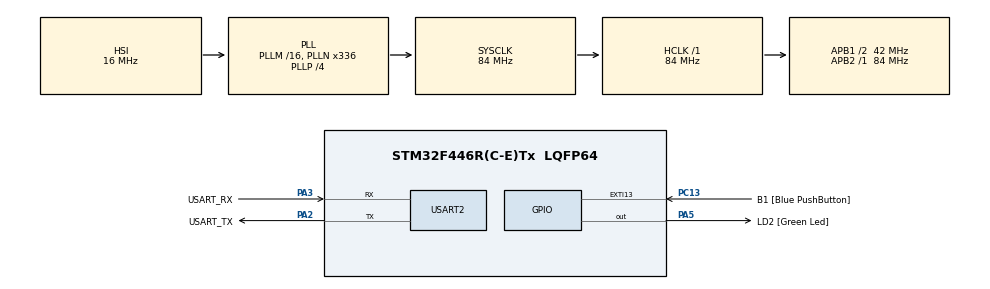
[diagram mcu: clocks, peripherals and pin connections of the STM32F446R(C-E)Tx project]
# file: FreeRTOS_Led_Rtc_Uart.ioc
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FREERTOS.Tasks01=defaultTask,24,128,StartDefaultTask,Default,NULL,Dynamic,NULL,NULL;LedTask,11,128,LedFunction,Default,NULL,Dynamic,NULL,NULL;RtcUartTask,32,128,RtcUartFunction,Default,NULL,Dynamic,NULL,NULL
FREERTOS.configUSE_NEWLIB_REENTRANT=1
Mcu.Family=STM32F4
Mcu.Name=STM32F446R(C-E)Tx
Mcu.Package=LQFP64
NVIC.PriorityGroup=NVIC_PRIORITYGROUP_4
NVIC.TIM5_IRQn=true\:15\:0\:false\:false\:true\:false\:false\:true
NVIC.TimeBase=TIM5_IRQn
NVIC.TimeBaseIP=TIM5
PA13.GPIO_Label=TMS
PA13.Mode=Serial_Wire
PA13.Signal=SYS_JTMS-SWDIO
PA14.GPIO_Label=TCK
PA14.Mode=Serial_Wire
PA14.Signal=SYS_JTCK-SWCLK
PA2.GPIO_Label=USART_TX
PA2.Mode=Asynchronous
PA2.Signal=USART2_TX
PA3.GPIO_Label=USART_RX
PA3.Mode=Asynchronous
PA3.Signal=USART2_RX
PA5.GPIO_Label=LD2 [Green Led]
PA5.Signal=GPIO_Output
PB3.GPIO_Label=SWO
PB3.Signal=SYS_JTDO-SWO
PC13.GPIO_Label=B1 [Blue PushButton]
PC13.GPIO_ModeDefaultEXTI=GPIO_MODE_IT_FALLING
PC13.Signal=GPXTI13
PC14-OSC32_IN.Mode=LSE-External-Oscillator
PC14-OSC32_IN.Signal=RCC_OSC32_IN
PC15-OSC32_OUT.Mode=LSE-External-Oscillator
PC15-OSC32_OUT.Signal=RCC_OSC32_OUT
PH0-OSC_IN.Signal=RCC_OSC_IN
PH1-OSC_OUT.Signal=RCC_OSC_OUT
ProjectManager.HeapSize=0x200
ProjectManager.StackSize=0x400
ProjectManager.TargetToolchain=STM32CubeIDE
RCC.AHBFreq_Value=84000000
RCC.APB1CLKDivider=RCC_HCLK_DIV2
RCC.APB1Freq_Value=42000000
RCC.APB1TimFreq_Value=84000000
RCC.APB2Freq_Value=84000000
RCC.APB2TimFreq_Value=84000000
RCC.CortexFreq_Value=84000000
RCC.FLatency-AdvancedSettings=FLASH_LATENCY_2
RCC.HCLKFreq_Value=84000000
RCC.HSE_VALUE=8000000
RCC.HSI_VALUE=16000000
RCC.PLLN=336
RCC.PLLP=RCC_PLLP_DIV4
RCC.SYSCLKFreq_VALUE=84000000
RCC.SYSCLKSource=RCC_SYSCLKSOURCE_PLLCLK
RCC.USBFreq_Value=168000000
RCC.VCOOutputFreq_Value=336000000
RTC.Date=11
RTC.Hours=9
RTC.Minutes=59
RTC.Month=RTC_MONTH_APRIL
RTC.Seconds=55
RTC.Year=23
USART2.VirtualMode=VM_ASYNC
VP_FREERTOS_VS_CMSIS_V2.Mode=CMSIS_V2
VP_RTC_VS_RTC_Activate.Mode=RTC_Enabled
VP_RTC_VS_RTC_Calendar.Mode=RTC_Calendar
VP_SYS_VS_tim5.Mode=TIM5
board=NUCLEO-F446RE

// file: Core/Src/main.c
/* USER CODE BEGIN Header */
/**
  ******************************************************************************
  * @file           : main.c
  * @brief          : Main program body
  ******************************************************************************
  * @attention
  *
  * Copyright (c) 2023 STMicroelectronics.
  * All rights reserved.
  *
  * This software is licensed under terms that can be found in the LICENSE file
  * in the root directory of this software component.
  * If no LICENSE file comes with this software, it is provided AS-IS.
  *
  ******************************************************************************
  */
/* USER CODE END Header */
#include "main.h"
#include "cmsis_os.h"

RTC_HandleTypeDef hrtc;

UART_HandleTypeDef huart2;

/* Definitions for defaultTask */
osThreadId_t defaultTaskHandle;
const osThreadAttr_t defaultTask_attributes = {
  .name = "defaultTask",
  .stack_size = 128 * 4,
  .priority = (osPriority_t) osPriorityNormal,
};
/* Definitions for LedTask */
osThreadId_t LedTaskHandle;
const osThreadAttr_t LedTask_attributes = {
  .name = "LedTask",
  .stack_size = 128 * 4,
  .priority = (osPriority_t) osPriorityLow3,
};
/* Definitions for RtcUartTask */
osThreadId_t RtcUartTaskHandle;
const osThreadAttr_t RtcUartTask_attributes = {
  .name = "RtcUartTask",
  .stack_size = 128 * 4,
  .priority = (osPriority_t) osPriorityAboveNormal,
};

void SystemClock_Config(void);
static void MX_GPIO_Init(void);
static void MX_RTC_Init(void);
static void MX_USART2_UART_Init(void);
void StartDefaultTask(void *argument);
void LedFunction(void *argument);
void RtcUartFunction(void *argument);

int main(void)
{

  /* MCU Configuration--------------------------------------------------------*/

  /* Reset of all peripherals, Initializes the Flash interface and the Systick. */
  HAL_Init();

  /* Configure the system clock */
  SystemClock_Config();

  /* Initialize all configured peripherals */
  MX_GPIO_Init();
  MX_RTC_Init();
  MX_USART2_UART_Init();

  /* Init scheduler */
  osKernelInitialize();

  /* Create the thread(s) */
  /* creation of defaultTask */
  defaultTaskHandle = osThreadNew(StartDefaultTask, NULL, &defaultTask_attributes);

  /* creation of LedTask */
  LedTaskHandle = osThreadNew(LedFunction, NULL, &LedTask_attributes);

  /* creation of RtcUartTask */
  RtcUartTaskHandle = osThreadNew(RtcUartFunction, NULL, &RtcUartTask_attributes);

  /* Start scheduler */
  osKernelStart();

  /* We should never get here as control is now taken by the scheduler */
  /* Infinite loop */
  while (1)
  {

  }
}

void SystemClock_Config(void)
{
  RCC_OscInitTypeDef RCC_OscInitStruct = {0};
  RCC_ClkInitTypeDef RCC_ClkInitStruct = {0};

  /** Configure the main internal regulator output voltage
  */
  __HAL_RCC_PWR_CLK_ENABLE();
  __HAL_PWR_VOLTAGESCALING_CONFIG(PWR_REGULATOR_VOLTAGE_SCALE3);
  /** Initializes the RCC Oscillators according to the specified parameters
  * in the RCC_OscInitTypeDef structure.
  */
  RCC_OscInitStruct.OscillatorType = RCC_OSCILLATORTYPE_HSI|RCC_OSCILLATORTYPE_LSI;
  RCC_OscInitStruct.LSEState = RCC_LSE_ON;
  RCC_OscInitStruct.HSIState = RCC_HSI_ON;
  RCC_OscInitStruct.HSICalibrationValue = RCC_HSICALIBRATION_DEFAULT;
  RCC_OscInitStruct.LSIState = RCC_LSI_ON;
  RCC_OscInitStruct.PLL.PLLState = RCC_PLL_ON;
  RCC_OscInitStruct.PLL.PLLSource = RCC_PLLSOURCE_HSI;
  RCC_OscInitStruct.PLL.PLLM = 16;
  RCC_OscInitStruct.PLL.PLLN = 336;
  RCC_OscInitStruct.PLL.PLLP = RCC_PLLP_DIV4;
  RCC_OscInitStruct.PLL.PLLQ = 2;
  RCC_OscInitStruct.PLL.PLLR = 2;
  if (HAL_RCC_OscConfig(&RCC_OscInitStruct) != HAL_OK)
  {
    Error_Handler();
  }
  /** Initializes the CPU, AHB and APB buses clocks
  */
  RCC_ClkInitStruct.ClockType = RCC_CLOCKTYPE_HCLK|RCC_CLOCKTYPE_SYSCLK
                              |RCC_CLOCKTYPE_PCLK1|RCC_CLOCKTYPE_PCLK2;
  RCC_ClkInitStruct.SYSCLKSource = RCC_SYSCLKSOURCE_PLLCLK;
  RCC_ClkInitStruct.AHBCLKDivider = RCC_SYSCLK_DIV1;
  RCC_ClkInitStruct.APB1CLKDivider = RCC_HCLK_DIV2;
  RCC_ClkInitStruct.APB2CLKDivider = RCC_HCLK_DIV1;

  if (HAL_RCC_ClockConfig(&RCC_ClkInitStruct, FLASH_LATENCY_2) != HAL_OK)
  {
    Error_Handler();
  }
}

static void MX_RTC_Init(void)
{

  RTC_TimeTypeDef sTime = {0};
  RTC_DateTypeDef sDate = {0};

  /** Initialize RTC Only
  */
  hrtc.Instance = RTC;
  hrtc.Init.HourFormat = RTC_HOURFORMAT_24;
  hrtc.Init.AsynchPrediv = 127;
  hrtc.Init.SynchPrediv = 255;
  hrtc.Init.OutPut = RTC_OUTPUT_DISABLE;
  hrtc.Init.OutPutPolarity = RTC_OUTPUT_POLARITY_HIGH;
  hrtc.Init.OutPutType = RTC_OUTPUT_TYPE_OPENDRAIN;
  if (HAL_RTC_Init(&hrtc) != HAL_OK)
  {
    Error_Handler();
  }

  /** Initialize RTC and set the Time and Date
  */
  sTime.Hours = 0x9;
  sTime.Minutes = 0x59;
  sTime.Seconds = 0x55;
  sTime.DayLightSaving = RTC_DAYLIGHTSAVING_NONE;
  sTime.StoreOperation = RTC_STOREOPERATION_RESET;
  if (HAL_RTC_SetTime(&hrtc, &sTime, RTC_FORMAT_BCD) != HAL_OK)
  {
    Error_Handler();
  }
  sDate.WeekDay = RTC_WEEKDAY_MONDAY;
  sDate.Month = RTC_MONTH_APRIL;
  sDate.Date = 0x11;
  sDate.Year = 0x23;

  if (HAL_RTC_SetDate(&hrtc, &sDate, RTC_FORMAT_BCD) != HAL_OK)
  {
    Error_Handler();
  }

}

static void MX_USART2_UART_Init(void)
{

  huart2.Instance = USART2;
  huart2.Init.BaudRate = 115200;
  huart2.Init.WordLength = UART_WORDLENGTH_8B;
  huart2.Init.StopBits = UART_STOPBITS_1;
  huart2.Init.Parity = UART_PARITY_NONE;
  huart2.Init.Mode = UART_MODE_TX_RX;
  huart2.Init.HwFlowCtl = UART_HWCONTROL_NONE;
  huart2.Init.OverSampling = UART_OVERSAMPLING_16;
  if (HAL_UART_Init(&huart2) != HAL_OK)
  {
    Error_Handler();
  }

}

static void MX_GPIO_Init(void)
{
  GPIO_InitTypeDef GPIO_InitStruct = {0};

  /* GPIO Ports Clock Enable */
  __HAL_RCC_GPIOC_CLK_ENABLE();
  __HAL_RCC_GPIOH_CLK_ENABLE();
  __HAL_RCC_GPIOA_CLK_ENABLE();
  __HAL_RCC_GPIOB_CLK_ENABLE();

  /*Configure GPIO pin Output Level */
  HAL_GPIO_WritePin(LD2_GPIO_Port, LD2_Pin, GPIO_PIN_RESET);

  /*Configure GPIO pin : B1_Pin */
  GPIO_InitStruct.Pin = B1_Pin;
  GPIO_InitStruct.Mode = GPIO_MODE_IT_FALLING;
  GPIO_InitStruct.Pull = GPIO_NOPULL;
  HAL_GPIO_Init(B1_GPIO_Port, &GPIO_InitStruct);

  /*Configure GPIO pin : LD2_Pin */
  GPIO_InitStruct.Pin = LD2_Pin;
  GPIO_InitStruct.Mode = GPIO_MODE_OUTPUT_PP;
  GPIO_InitStruct.Pull = GPIO_NOPULL;
  GPIO_InitStruct.Speed = GPIO_SPEED_FREQ_LOW;
  HAL_GPIO_Init(LD2_GPIO_Port, &GPIO_InitStruct);

}

void StartDefaultTask(void *argument)
{
  for(;;)
  {
    osDelay(1);
  }
}

void LedFunction(void *argument)
{
  /* USER CODE BEGIN LedFunction */
  /* Infinite loop */
  for(;;)
  {
	HAL_GPIO_TogglePin(GPIOA, GPIO_PIN_5);
    osDelay(1000);
  }
  /* USER CODE END LedFunction */
}

void RtcUartFunction(void *argument)
{
  /* USER CODE BEGIN RtcUartFunction */
  RTC_DateTypeDef getDate;
  RTC_TimeTypeDef getTime;
  uint8_t transmitBuffer[40];
  /* Infinite loop */
  for(;;)
  {
	if( HAL_RTC_GetTime(&hrtc, &getTime, RTC_FORMAT_BCD) != HAL_OK)
	{
		Error_Handler();
	}
	osDelay(1000);
	if( HAL_RTC_GetDate(&hrtc, &getDate, RTC_FORMAT_BCD) != HAL_OK)
	{
		Error_Handler();
	}
	sprintf(transmitBuffer,"Time- %x:%x:%x\r\n", getTime.Hours, getTime.Minutes, getTime.Seconds);
	HAL_UART_Transmit(&huart2, transmitBuffer, strlen(transmitBuffer), 100);
    osDelay(4000);
  }
  /* USER CODE END RtcUartFunction */
}

void HAL_TIM_PeriodElapsedCallback(TIM_HandleTypeDef *htim)
{
  if (htim->Instance == TIM5) {
    HAL_IncTick();
  }
}

void Error_Handler(void)
{
  __disable_irq();
  while (1)
  {
  }
}
